# STM32F072xB register map
File version: 1.0
Registers are 32-bit, read-write, reset 0x0 unless marked. A register's access mark holds for its fields unless they carry their own. Offsets are from the block's base; [hi:lo] are bit positions; {n}, {i} and the like mark numbered series.

## RCC — Reset and Clock Control
Base 0x40021000
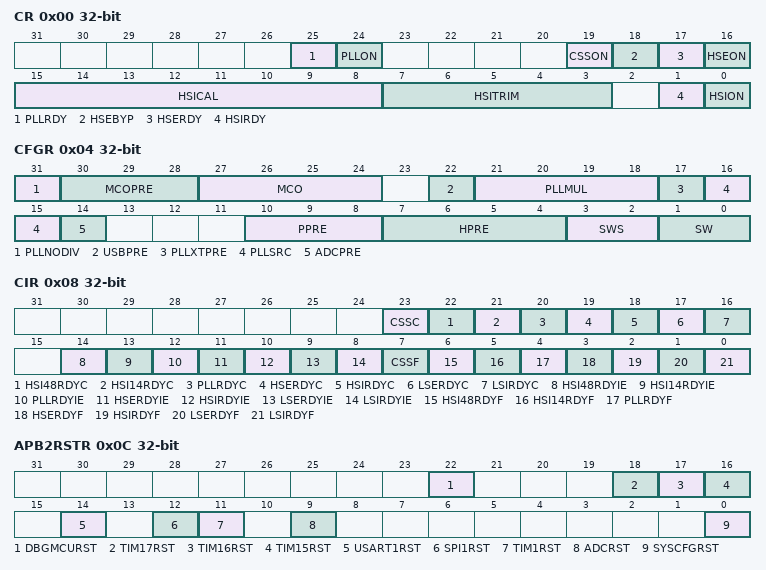
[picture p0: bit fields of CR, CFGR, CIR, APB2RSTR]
0x00 CR — RCC clock control register
  [25] PLLRDY — PLL clock ready flag
  [24] PLLON — PLL enable
  [19] CSSON — Clock Security System enable
  [18] HSEBYP — External High Speed clock Bypass
  [17] HSERDY — External High Speed clock ready flag
  [16] HSEON — External High Speed clock enable
  [15:8] HSICAL — Internal High Speed clock Calibration
  [7:3] HSITRIM — Internal High Speed clock trimming
  [1] HSIRDY — Internal High Speed clock ready flag
  [0] HSION — Internal High Speed clock enable
0x04 CFGR — RCC clock configuration register
  [31] PLLNODIV — PLL is not divided to MCO
  [30:28] MCOPRE — MCO prescaler
  [27:24] MCO — MCO[3:0] bits (Microcontroller Clock Output)
  [22] USBPRE — USB prescaler
  [21:18] PLLMUL — PLLMUL[3:0] bits (PLL multiplication factor)
    {v}=MUL_{v+2} (PLL input clock*{v+2}) (v=0..14)
  [17] PLLXTPRE — HSE divider for PLL entry
  [16:15] PLLSRC — PLL entry clock source
    0=NONE (No clock selected as main PLL entry clock source); 1=HSI (HSI/PREDIV clock selected as PLL entry clock source); 2=HSE (HSE/PREDIV clock selected as PLL entry clock source); 3=HSI48 (HSI48/PREDIV clock selected as PLL entry clock source)
  [14] ADCPRE — ADCPRE bit (ADC prescaler)
  [10:8] PPRE — PRE[2:0] bits (APB prescaler)
    0=DIV_1 (HCLK not divided); 4=DIV_2 (HCLK divided by 2); 5=DIV_4 (HCLK divided by 4); 6=DIV_8 (HCLK divided by 8); 7=DIV_16 (HCLK divided by 16)
  [7:4] HPRE — HPRE[3:0] bits (AHB prescaler)
    0=DIV_1 (SYSCLK not divided); 8=DIV_2 (SYSCLK divided by 2); 9=DIV_4 (SYSCLK divided by 4); 10=DIV_8 (SYSCLK divided by 8); 11=DIV_16 (SYSCLK divided by 16); 12=DIV_64 (SYSCLK divided by 64); 13=DIV_128 (SYSCLK divided by 128); 14=DIV_256 (SYSCLK divided by 256); 15=DIV_512 (SYSCLK divided by 512)
  [3:2] SWS — SWS[1:0] bits (System Clock Switch Status)
    0=HSI (HSI used as system clock); 1=HSE (HSE used as system clock); 2=PLL (PLL used as system clock); 3=HSI48 (HSI48 used as system clock)
  [1:0] SW — SW[1:0] bits (System clock Switch)
    0=HSI (HSI selection as system clock); 1=HSE (HSE selection as system clock); 2=PLL (PLL selection as system clock); 3=HSI48 (HSI48 selection as system clock)
0x08 CIR — RCC clock interrupt register
  [23] CSSC — Clock Security System Interrupt Clear
  [22] HSI48RDYC — HSI48 Ready Interrupt Clear
  [21] HSI14RDYC — HSI14 Ready Interrupt Clear
  [20] PLLRDYC — PLL Ready Interrupt Clear
  [19] HSERDYC — HSE Ready Interrupt Clear
  [18] HSIRDYC — HSI Ready Interrupt Clear
  [17] LSERDYC — LSE Ready Interrupt Clear
  [16] LSIRDYC — LSI Ready Interrupt Clear
  [14] HSI48RDYIE — HSI48 Ready Interrupt Enable
  [13] HSI14RDYIE — HSI14 Ready Interrupt Enable
  [12] PLLRDYIE — PLL Ready Interrupt Enable
  [11] HSERDYIE — HSE Ready Interrupt Enable
  [10] HSIRDYIE — HSI Ready Interrupt Enable
  [9] LSERDYIE — LSE Ready Interrupt Enable
  [8] LSIRDYIE — LSI Ready Interrupt Enable
  [7] CSSF — Clock Security System Interrupt flag
  [6] HSI48RDYF — HSI48 Ready Interrupt flag
  [5] HSI14RDYF — HSI14 Ready Interrupt flag
  [4] PLLRDYF — PLL Ready Interrupt flag
  [3] HSERDYF — HSE Ready Interrupt flag
  [2] HSIRDYF — HSI Ready Interrupt flag
  [1] LSERDYF — LSE Ready Interrupt flag
  [0] LSIRDYF — LSI Ready Interrupt flag
0x0C APB2RSTR — RCC APB2 peripheral reset register
  [22] DBGMCURST — DBGMCU reset
  [18] TIM17RST — TIM17 reset
  [17] TIM16RST — TIM16 reset
  [16] TIM15RST — TIM15 reset
  [14] USART1RST — USART1 reset
  [12] SPI1RST — SPI1 reset
  [11] TIM1RST — TIM1 reset
  [9] ADCRST — ADC reset
  [0] SYSCFGRST — SYSCFG reset
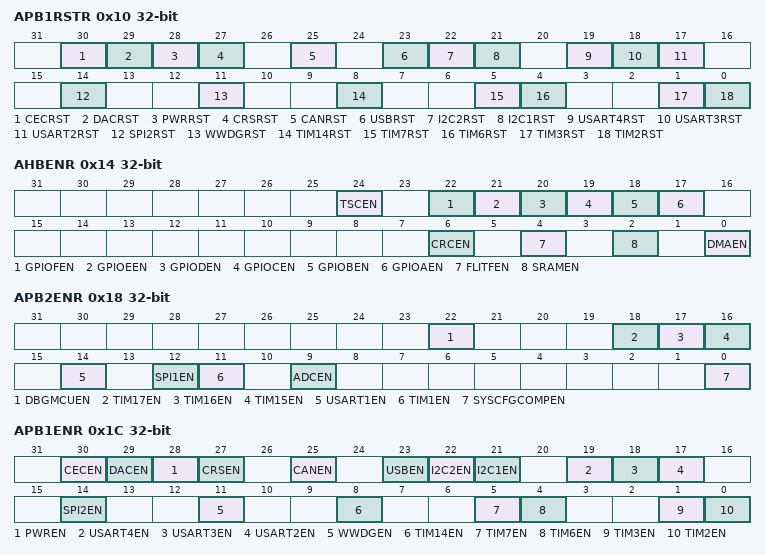
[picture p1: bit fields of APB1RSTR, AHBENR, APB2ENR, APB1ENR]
0x10 APB1RSTR — RCC APB1 peripheral reset register
  [30] CECRST — CEC reset
  [29] DACRST — DAC reset
  [28] PWRRST — PWR reset
  [27] CRSRST — CRS reset
  [25] CANRST — CAN reset
  [23] USBRST — USB reset
  [22] I2C2RST — I2C 2 reset
  [21] I2C1RST — I2C 1 reset
  [19] USART4RST — USART 4 reset
  [18] USART3RST — USART 3 reset
  [17] USART2RST — USART 2 reset
  [14] SPI2RST — SPI2 reset
  [11] WWDGRST — Window Watchdog reset
  [8] TIM14RST — Timer 14 reset
  [5] TIM7RST — Timer 7 reset
  [4] TIM6RST — Timer 6 reset
  [1] TIM3RST — Timer 3 reset
  [0] TIM2RST — Timer 2 reset
0x14 AHBENR — RCC AHB peripheral clock register
  [24] TSCEN — TS controller clock enable
  [22] GPIOFEN — GPIOF clock enable
  [21] GPIOEEN — GPIOE clock enable
  [20] GPIODEN — GPIOD clock enable
  [19] GPIOCEN — GPIOC clock enable
  [18] GPIOBEN — GPIOB clock enable
  [17] GPIOAEN — GPIOA clock enable
  [6] CRCEN — CRC clock enable
  [4] FLITFEN — FLITF clock enable
  [2] SRAMEN — SRAM interface clock enable
  [0] DMAEN — DMA1 clock enable
0x18 APB2ENR — RCC APB2 peripheral clock enable register
  [22] DBGMCUEN — DBGMCU clock enable
  [18] TIM17EN — TIM17 clock enable
  [17] TIM16EN — TIM16 clock enable
  [16] TIM15EN — TIM15 clock enable
  [14] USART1EN — USART1 clock enable
  [12] SPI1EN — SPI1 clock enable
  [11] TIM1EN — TIM1 clock enable
  [9] ADCEN — ADC1 clock enable
  [0] SYSCFGCOMPEN — SYSCFG and comparator clock enable
0x1C APB1ENR — RCC APB1 peripheral clock enable register
  [30] CECEN — CEC clock enable
  [29] DACEN — DAC clock enable
  [28] PWREN — PWR clock enable
  [27] CRSEN — CRS clock enable
  [25] CANEN — CAN clock enable
  [23] USBEN — USB clock enable
  [22] I2C2EN — I2C2 clock enable
  [21] I2C1EN — I2C1 clock enable
  [19] USART4EN — USART4 clock enable
  [18] USART3EN — USART3 clock enable
  [17] USART2EN — USART2 clock enable
  [14] SPI2EN — SPI2 clock enable
  [11] WWDGEN — Window Watchdog clock enable
  [8] TIM14EN — Timer 14 clock enable
  [5] TIM7EN — Timer 7 clock enable
  [4] TIM6EN — Timer 6 clock enable
  [1] TIM3EN — Timer 3 clock enable
  [0] TIM2EN — Timer 2 clock enable
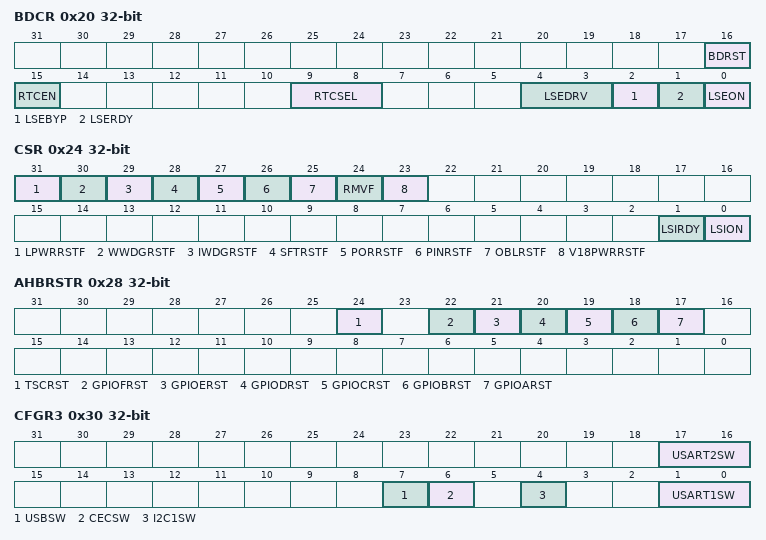
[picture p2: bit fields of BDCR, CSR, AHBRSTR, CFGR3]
0x20 BDCR — RCC Backup domain control register
  [16] BDRST — Backup domain software reset
  [15] RTCEN — RTC clock enable
  [9:8] RTCSEL — RTCSEL[1:0] bits (RTC clock source selection)
    0=NONE (No clock used as RTC clock); 1=LSE (LSE oscillator clock used as RTC clock); 2=LSI (LSI oscillator clock used as RTC clock); 3=HSE_DIV32 (HSE oscillator clock divided by 32 used as RTC clock)
  [4:3] LSEDRV — LSEDRV[1:0] bits (LSE Osc. drive capability)
    0=LOW (Xtal mode lower driving capability); 2=MEDIUMLOW (Xtal mode medium low driving capability); 1=MEDIUMHIGH (Xtal mode medium high driving capability); 3=HIGH (Xtal mode higher driving capability)
  [2] LSEBYP — External Low Speed oscillator Bypass
  [1] LSERDY — External Low Speed oscillator Ready
  [0] LSEON — External Low Speed oscillator enable
0x24 CSR — RCC clock control & status register
  [31] LPWRRSTF — Low-Power reset flag
  [30] WWDGRSTF — Window watchdog reset flag
  [29] IWDGRSTF — Independent Watchdog reset flag
  [28] SFTRSTF — Software Reset flag
  [27] PORRSTF — POR/PDR reset flag
  [26] PINRSTF — PIN reset flag
  [25] OBLRSTF — OBL reset flag
  [24] RMVF — Remove reset flag
  [23] V18PWRRSTF — V1.8 power domain reset flag
  [1] LSIRDY — Internal Low Speed oscillator Ready
  [0] LSION — Internal Low Speed oscillator enable
0x28 AHBRSTR — RCC AHB peripheral reset register
  [24] TSCRST — TS reset
  [22] GPIOFRST — GPIOF reset
  [21] GPIOERST — GPIOE reset
  [20] GPIODRST — GPIOD reset
  [19] GPIOCRST — GPIOC reset
  [18] GPIOBRST — GPIOB reset
  [17] GPIOARST — GPIOA reset
0x2C CFGR2 — RCC clock configuration register 2
  [3:0] PREDIV — PREDIV[3:0] bits
    0=DIV_1 (PREDIV input clock not divided); {v}=DIV_{v+1} (PREDIV input clock divided by {v+1}) (v=1..15)
0x30 CFGR3 — RCC clock configuration register 3
  [17:16] USART2SW — USART2SW[1:0] bits
  [7] USBSW — USBSW bits
    0=HSI48 (HSI48 oscillator clock used as USB clock source); 1=PLL (PLL selected as USB clock source)
  [6] CECSW — CECSW bits
    0=HSI_DIV244 (HSI clock divided by 244 selected as HDMI CEC entry clock source); 1=LSE (LSE clock selected as HDMI CEC entry clock source)
  [4] I2C1SW — I2C1SW bits
    0=HSI (HSI oscillator clock used as I2C1 clock source); 1=SYSCLK (System clock selected as I2C1 clock source)
  [1:0] USART1SW — USART1SW[1:0] bits
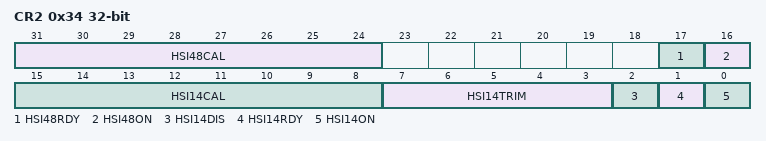
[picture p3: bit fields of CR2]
0x34 CR2 — RCC clock control register 2
  [31:24] HSI48CAL — Internal High Speed 48MHz clock Calibration
  [17] HSI48RDY — Internal High Speed 48MHz clock ready flag
  [16] HSI48ON — Internal High Speed 48MHz clock enable
  [15:8] HSI14CAL — Internal High Speed 14MHz clock Calibration
  [7:3] HSI14TRIM — Internal High Speed 14MHz clock trimming
  [2] HSI14DIS — Internal High Speed 14MHz clock disable
  [1] HSI14RDY — Internal High Speed 14MHz clock ready flag
  [0] HSI14ON — Internal High Speed 14MHz clock enable
